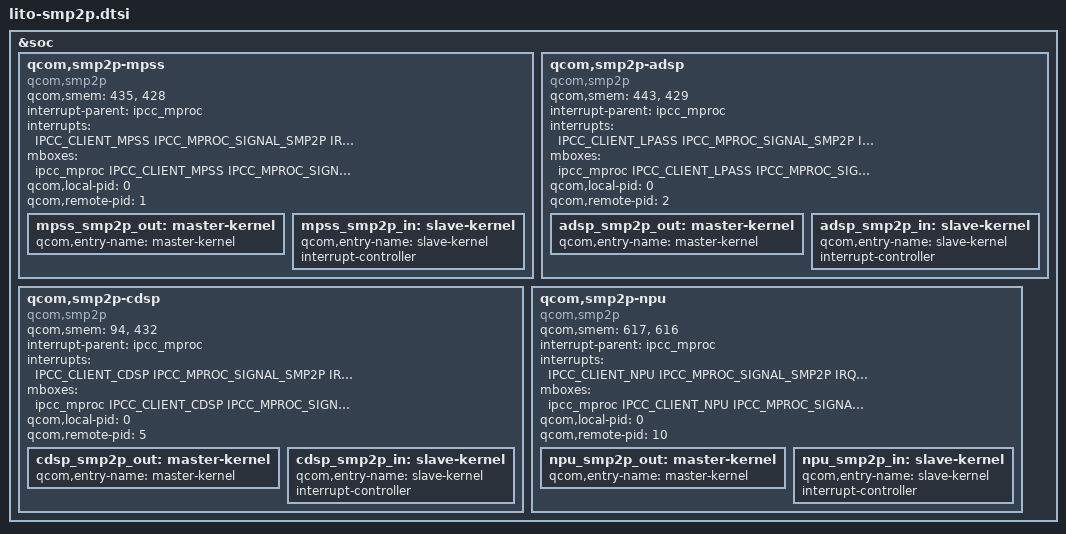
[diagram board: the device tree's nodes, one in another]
// SPDX-License-Identifier: GPL-2.0-only
/*
 * Copyright (c) 2019, The Linux Foundation. All rights reserved.
 */

#include <dt-bindings/interrupt-controller/arm-gic.h>
#include <dt-bindings/soc/qcom,ipcc.h>

&soc {

	qcom,smp2p-mpss {
		compatible = "qcom,smp2p";
		qcom,smem = <435>, <428>;
		interrupt-parent = <&ipcc_mproc>;
		interrupts = <IPCC_CLIENT_MPSS IPCC_MPROC_SIGNAL_SMP2P
			      IRQ_TYPE_EDGE_RISING>;
		mboxes = <&ipcc_mproc IPCC_CLIENT_MPSS IPCC_MPROC_SIGNAL_SMP2P>;
		qcom,local-pid = <0>;
		qcom,remote-pid = <1>;

		mpss_smp2p_out: master-kernel {
			qcom,entry-name = "master-kernel";
			#qcom,smem-state-cells = <1>;
		};

		mpss_smp2p_in: slave-kernel {
			qcom,entry-name = "slave-kernel";
			interrupt-controller;
			#interrupt-cells = <2>;
		};
	};

	qcom,smp2p-adsp {
		compatible = "qcom,smp2p";
		qcom,smem = <443>, <429>;
		interrupt-parent = <&ipcc_mproc>;
		interrupts = <IPCC_CLIENT_LPASS IPCC_MPROC_SIGNAL_SMP2P
			      IRQ_TYPE_EDGE_RISING>;
		mboxes = <&ipcc_mproc IPCC_CLIENT_LPASS
			  IPCC_MPROC_SIGNAL_SMP2P>;
		qcom,local-pid = <0>;
		qcom,remote-pid = <2>;

		adsp_smp2p_out: master-kernel {
			qcom,entry-name = "master-kernel";
			#qcom,smem-state-cells = <1>;
		};

		adsp_smp2p_in: slave-kernel {
			qcom,entry-name = "slave-kernel";
			interrupt-controller;
			#interrupt-cells = <2>;
		};
	};

	qcom,smp2p-cdsp {
		compatible = "qcom,smp2p";
		qcom,smem = <94>, <432>;
		interrupt-parent = <&ipcc_mproc>;
		interrupts = <IPCC_CLIENT_CDSP IPCC_MPROC_SIGNAL_SMP2P
			      IRQ_TYPE_EDGE_RISING>;
		mboxes = <&ipcc_mproc IPCC_CLIENT_CDSP IPCC_MPROC_SIGNAL_SMP2P>;
		qcom,local-pid = <0>;
		qcom,remote-pid = <5>;

		cdsp_smp2p_out: master-kernel {
			qcom,entry-name = "master-kernel";
			#qcom,smem-state-cells = <1>;
		};

		cdsp_smp2p_in: slave-kernel {
			qcom,entry-name = "slave-kernel";
			interrupt-controller;
			#interrupt-cells = <2>;
		};
	};

	qcom,smp2p-npu {
		compatible = "qcom,smp2p";
		qcom,smem = <617>, <616>;
		interrupt-parent = <&ipcc_mproc>;
		interrupts = <IPCC_CLIENT_NPU IPCC_MPROC_SIGNAL_SMP2P
			      IRQ_TYPE_EDGE_RISING>;
		mboxes = <&ipcc_mproc IPCC_CLIENT_NPU IPCC_MPROC_SIGNAL_SMP2P>;
		qcom,local-pid = <0>;
		qcom,remote-pid = <10>;

		npu_smp2p_out: master-kernel {
			qcom,entry-name = "master-kernel";
			#qcom,smem-state-cells = <1>;
		};

		npu_smp2p_in: slave-kernel {
			qcom,entry-name = "slave-kernel";
			interrupt-controller;
			#interrupt-cells = <2>;
		};
	};
};
